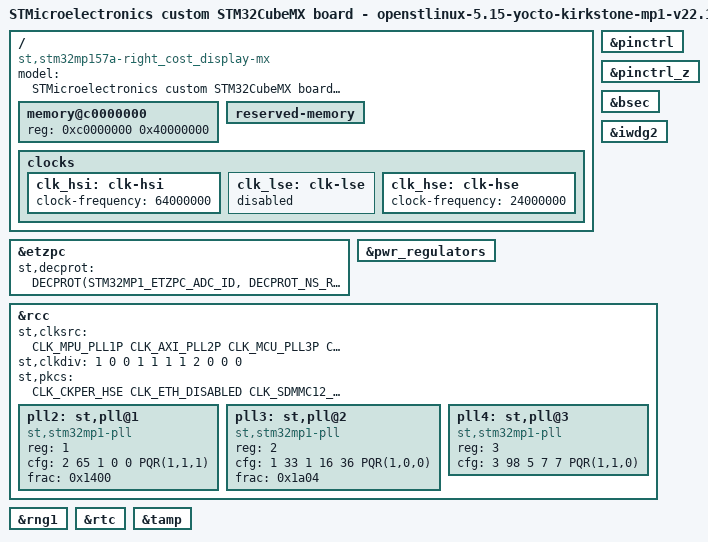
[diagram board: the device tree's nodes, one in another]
/* SPDX-License-Identifier: (GPL-2.0+ OR BSD-3-Clause) */
/*
 * Copyright (C) STMicroelectronics 2023 - All Rights Reserved
 * Author: STM32CubeMX code generation for STMicroelectronics.
 */

/* For more information on Device Tree configuration, please refer to
 * https://wiki.st.com/stm32mpu/wiki/Category:Device_tree_configuration
 */

/dts-v1/;
#include <dt-bindings/pinctrl/stm32-pinfunc.h>
#include <dt-bindings/clock/stm32mp1-clksrc.h>
#include <dt-bindings/soc/stm32mp15-etzpc.h>

#include "stm32mp157.dtsi"
#include "stm32mp15xa.dtsi"
#include "stm32mp15xxab-pinctrl.dtsi"

/* USER CODE BEGIN includes */
/* USER CODE END includes */

/ {
	model = "STMicroelectronics custom STM32CubeMX board - openstlinux-5.15-yocto-kirkstone-mp1-v22.11.23";
	compatible = "st,stm32mp157a-right_cost_display-mx", "st,stm32mp157";

	memory@c0000000 {
		device_type = "memory";
		reg = <0xc0000000 0x40000000>;

		/* USER CODE BEGIN memory */
		/* USER CODE END memory */
	};

	reserved-memory {
		#address-cells = <1>;
		#size-cells = <1>;
		ranges;

		/* USER CODE BEGIN reserved-memory */
		/* USER CODE END reserved-memory */
	};

	/* USER CODE BEGIN root */
	/* USER CODE END root */

	clocks {
		/* USER CODE BEGIN clocks */
		/* USER CODE END clocks */

		clk_hsi: clk-hsi {
			clock-frequency = <64000000>;

			/* USER CODE BEGIN clk_hsi */
			/* USER CODE END clk_hsi */
		};
		clk_lse: clk-lse {
			status = "disabled";

			/* USER CODE BEGIN clk_lse */
			/* USER CODE END clk_lse */
		};
		clk_hse: clk-hse {
			clock-frequency = <24000000>;

			/* USER CODE BEGIN clk_hse */
			/* USER CODE END clk_hse */
		};
	};

}; /*root*/

/*Warning: the configuration of the secured GPIOs should be added in (addons) User Section*/
&pinctrl {
	/* USER CODE BEGIN pinctrl */
	/* USER CODE END pinctrl */
};

&pinctrl_z {
	/* USER CODE BEGIN pinctrl_z */
	/* USER CODE END pinctrl_z */
};

&bsec{
	status = "okay";

	/* USER CODE BEGIN bsec */
	/* USER CODE END bsec */
};

&etzpc{
	status = "okay";
	st,decprot = <
	/*"Non Secured" peripherals*/
	DECPROT(STM32MP1_ETZPC_ADC_ID, DECPROT_NS_RW, DECPROT_UNLOCK)
	DECPROT(STM32MP1_ETZPC_DMA1_ID, DECPROT_NS_RW, DECPROT_UNLOCK)
	DECPROT(STM32MP1_ETZPC_DMAMUX_ID, DECPROT_NS_RW, DECPROT_UNLOCK)
	DECPROT(STM32MP1_ETZPC_TT_FDCAN_ID, DECPROT_NS_RW, DECPROT_UNLOCK)
	DECPROT(STM32MP1_ETZPC_HASH1_ID, DECPROT_NS_RW, DECPROT_UNLOCK)
	DECPROT(STM32MP1_ETZPC_I2C4_ID, DECPROT_NS_RW, DECPROT_UNLOCK)
	DECPROT(STM32MP1_ETZPC_RNG1_ID, DECPROT_NS_RW, DECPROT_UNLOCK)
	DECPROT(STM32MP1_ETZPC_SDMMC3_ID, DECPROT_NS_RW, DECPROT_UNLOCK)
	DECPROT(STM32MP1_ETZPC_DLYBSD3_ID, DECPROT_NS_RW, DECPROT_UNLOCK)
	DECPROT(STM32MP1_ETZPC_TIM16_ID, DECPROT_NS_RW, DECPROT_UNLOCK)
	DECPROT(STM32MP1_ETZPC_TIM4_ID, DECPROT_NS_RW, DECPROT_UNLOCK)
	DECPROT(STM32MP1_ETZPC_UART4_ID, DECPROT_NS_RW, DECPROT_UNLOCK)
	DECPROT(STM32MP1_ETZPC_UART5_ID, DECPROT_NS_RW, DECPROT_UNLOCK)
	DECPROT(STM32MP1_ETZPC_USART1_ID, DECPROT_NS_RW, DECPROT_UNLOCK)
	DECPROT(STM32MP1_ETZPC_OTG_ID, DECPROT_NS_RW, DECPROT_UNLOCK)
	/*"NS_R S_W" peripherals*/
	DECPROT(STM32MP1_ETZPC_DDRCTRL_ID, DECPROT_NS_R_S_W, DECPROT_LOCK)
	DECPROT(STM32MP1_ETZPC_DDRPHYC_ID, DECPROT_NS_R_S_W, DECPROT_LOCK)
	/*"Secured" peripherals*/
	DECPROT(STM32MP1_ETZPC_STGENC_ID, DECPROT_S_RW, DECPROT_UNLOCK)
	/*"Mcu Isolation" peripherals*/
	DECPROT(STM32MP1_ETZPC_DMA2_ID, DECPROT_MCU_ISOLATION, DECPROT_UNLOCK)
	DECPROT(STM32MP1_ETZPC_TIM6_ID, DECPROT_MCU_ISOLATION, DECPROT_UNLOCK)

	/*Restriction: following IDs are not managed  - please to use User-Section if needed:
		  STM32MP1_ETZPC_SRAMx_ID  STM32MP1_ETZPC_RETRAM_ID  STM32MP1_ETZPC_BKPSRAM_ID*/

	/* USER CODE BEGIN etzpc_decprot */

	/*  CAN Peripheral assigned to A7 None Secure by default.
	    M4 CAN Addition not included by default, static TF-A copy with M4-CAN
		is available in /recipes-uboot/u-boot/files/tf-a_M4-CAN_emmc.stm32 */
	/* DECPROT(STM32MP1_ETZPC_TT_FDCAN_ID, DECPROT_MCU_ISOLATION, DECPROT_UNLOCK) */

		/*STM32CubeMX generates a basic and standard configuration for ETZPC.
		Additional device configurations can be added here if needed.
		"etzpc" node could be also overloaded in "addons" User-Section.*/
	/* USER CODE END etzpc_decprot */
	>;

	/* USER CODE BEGIN etzpc */
	/* USER CODE END etzpc */
};

&iwdg2{
	status = "okay";

	/* USER CODE BEGIN iwdg2 */
	/* USER CODE END iwdg2 */
};

&pwr_regulators{
	status = "okay";

	/* USER CODE BEGIN pwr_regulators */
	/* USER CODE END pwr_regulators */
};

&rcc{
	status = "okay";

	/* USER CODE BEGIN rcc */
	/* USER CODE END rcc */

	st,clksrc = <
		CLK_MPU_PLL1P
		CLK_AXI_PLL2P
		CLK_MCU_PLL3P
		CLK_PLL12_HSE
		CLK_PLL3_HSE
		CLK_PLL4_HSE
		CLK_RTC_LSI
		CLK_MCO1_DISABLED
		CLK_MCO2_DISABLED
	>;
	st,clkdiv = <
		1 		/*MPU*/
		0 		/*AXI*/
		0 		/*MCU*/
		1 		/*APB1*/
		1 		/*APB2*/
		1 		/*APB3*/
		1 		/*APB4*/
		2 		/*APB5*/
		0 		/*RTC*/
		0 		/*MCO1*/
		0 		/*MCO2*/
	>;
	st,pkcs = <
		CLK_CKPER_HSE
		CLK_ETH_DISABLED
		CLK_SDMMC12_PLL4P
		CLK_STGEN_HSE
		CLK_USBPHY_HSE
		CLK_SPI2S1_DISABLED
		CLK_SPI2S23_DISABLED
		CLK_SPI45_DISABLED
		CLK_SPI6_DISABLED
		CLK_I2C46_HSI
		CLK_SDMMC3_PLL4P
		CLK_USBO_USBPHY
		CLK_ADC_CKPER
		CLK_CEC_DISABLED
		CLK_I2C12_DISABLED
		CLK_I2C35_DISABLED
		CLK_UART1_HSI
		CLK_UART24_HSI
		CLK_UART35_HSI
		CLK_UART6_DISABLED
		CLK_UART78_DISABLED
		CLK_SPDIF_DISABLED
		CLK_FDCAN_HSE
		CLK_SAI1_DISABLED
		CLK_SAI2_DISABLED
		CLK_SAI3_DISABLED
		CLK_SAI4_DISABLED
		CLK_RNG1_CSI
		CLK_LPTIM1_DISABLED
		CLK_LPTIM23_DISABLED
		CLK_LPTIM45_DISABLED
	>;
	pll2:st,pll@1 {
		compatible = "st,stm32mp1-pll";
		reg = <1>;
		cfg = < 2 65 1 0 0 PQR(1,1,1) >;
		frac = < 0x1400 >;
	};
	pll3:st,pll@2 {
		compatible = "st,stm32mp1-pll";
		reg = <2>;
		cfg = < 1 33 1 16 36 PQR(1,0,0) >;
		frac = < 0x1a04 >;
	};
	pll4:st,pll@3 {
		compatible = "st,stm32mp1-pll";
		reg = <3>;
		cfg = < 3 98 5 7 7 PQR(1,1,0) >;
	};
};

&rng1{
	status = "okay";

	/* USER CODE BEGIN rng1 */
	/* USER CODE END rng1 */
};

&rtc{
	status = "okay";

	/* USER CODE BEGIN rtc */
	/* USER CODE END rtc */
};

&tamp{
	status = "okay";

	/* USER CODE BEGIN tamp */
	/* USER CODE END tamp */
};

/* USER CODE BEGIN addons */
/* USER CODE END addons */

